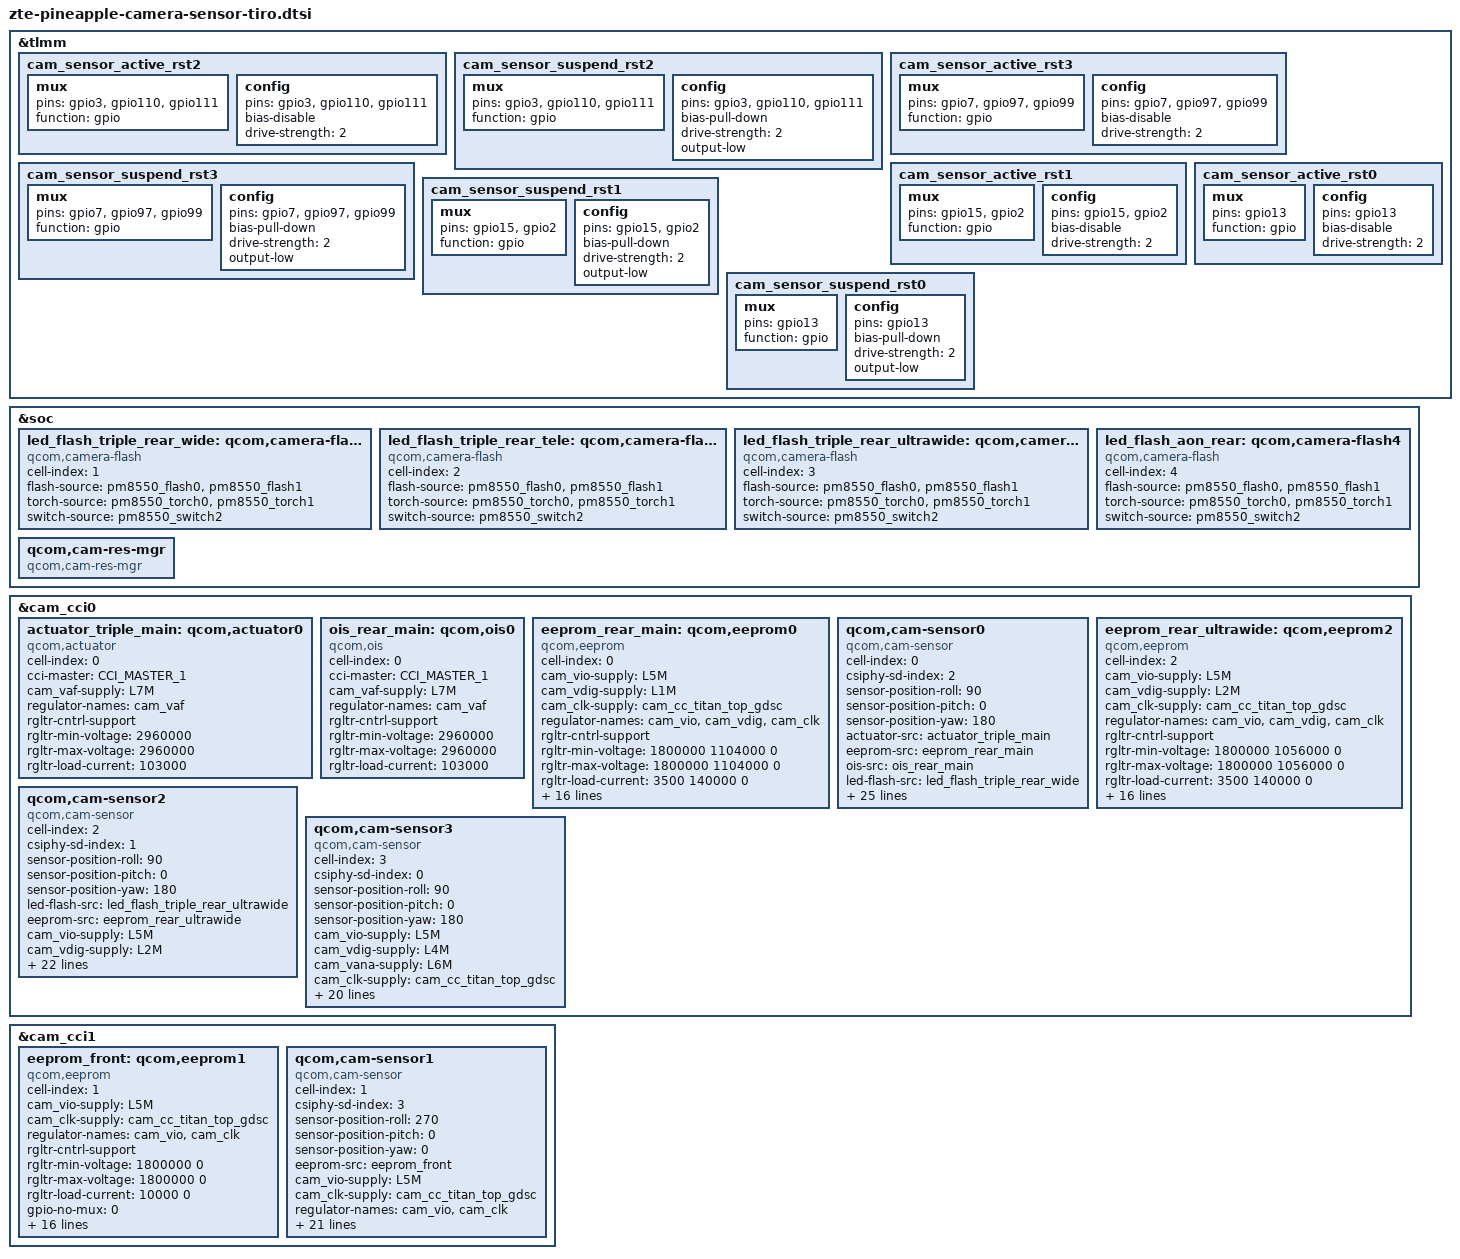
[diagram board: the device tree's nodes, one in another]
#include <dt-bindings/msm-camera.h>
&tlmm {
	cam_sensor_active_rst2: cam_sensor_active_rst2 {
		/* RESET 2 */
		mux {
			pins = "gpio3", "gpio110", "gpio111";
			function = "gpio";
		};

		config {
			pins = "gpio3", "gpio110", "gpio111";
			bias-disable; /* No PULL */
			drive-strength = <2>; /* 2 MA */
		};
	};

	cam_sensor_suspend_rst2: cam_sensor_suspend_rst2 {
		/* RESET 2 */
		mux {
			pins = "gpio3", "gpio110", "gpio111";
			function = "gpio";
		};

		config {
			pins = "gpio3", "gpio110", "gpio111";
			bias-pull-down; /* PULL DOWN */
			drive-strength = <2>; /* 2 MA */
			output-low;
		};
	};

	cam_sensor_active_rst3: cam_sensor_active_rst3 {
		/* RESET 3 */
		mux {
			pins = "gpio7", "gpio97", "gpio99";
			function = "gpio";
		};

		config {
			pins = "gpio7", "gpio97", "gpio99";
			bias-disable; /* No PULL */
			drive-strength = <2>; /* 2 MA */
		};
	};

	cam_sensor_suspend_rst3: cam_sensor_suspend_rst3 {
		/* RESET 3 */
		mux {
			pins = "gpio7", "gpio97", "gpio99";
			function = "gpio";
		};

		config {
			pins = "gpio7", "gpio97", "gpio99";
			bias-pull-down; /* PULL DOWN */
			drive-strength = <2>; /* 2 MA */
			output-low;
		};
	};

	cam_sensor_active_rst1: cam_sensor_active_rst1 {
		/* RESET 1 */
		mux {
			pins = "gpio15", "gpio2";
			function = "gpio";
		};

		config {
			pins = "gpio15", "gpio2";
			bias-disable; /* No PULL */
			drive-strength = <2>; /* 2 MA */
		};
	};

	cam_sensor_suspend_rst1: cam_sensor_suspend_rst1 {
		/* RESET 1 */
		mux {
			pins = "gpio15", "gpio2";
			function = "gpio";
		};

		config {
			pins = "gpio15", "gpio2";
			bias-pull-down; /* PULL DOWN */
			drive-strength = <2>; /* 2 MA */
			output-low;
		};
	};

	cam_sensor_active_rst0: cam_sensor_active_rst0 {
		/* RESET 0 */
		mux {
			pins = "gpio13";
			function = "gpio";
		};

		config {
			pins = "gpio13";
			bias-disable; /* No PULL */
			drive-strength = <2>; /* 2 MA */
		};
	};

	cam_sensor_suspend_rst0: cam_sensor_suspend_rst0 {
		/* RESET 0 */
		mux {
			pins = "gpio13";
			function = "gpio";
		};

		config {
			pins = "gpio13";
			bias-pull-down; /* PULL DOWN */
			drive-strength = <2>; /* 2 MA */
			output-low;
		};
	};
};

&soc {
	led_flash_triple_rear_wide: qcom,camera-flash1 {
		cell-index = <1>;
		compatible = "qcom,camera-flash";
		flash-source = <&pm8550_flash0 &pm8550_flash1>;
		torch-source = <&pm8550_torch0 &pm8550_torch1>;
		switch-source = <&pm8550_switch2>;
		status = "ok";
	};

	led_flash_triple_rear_tele: qcom,camera-flash2 {
		cell-index = <2>;
		compatible = "qcom,camera-flash";
		flash-source = <&pm8550_flash0 &pm8550_flash1>;
		torch-source = <&pm8550_torch0 &pm8550_torch1>;
		switch-source = <&pm8550_switch2>;
		status = "ok";
	};

	led_flash_triple_rear_ultrawide: qcom,camera-flash3 {
		cell-index = <3>;
		compatible = "qcom,camera-flash";
		flash-source = <&pm8550_flash0 &pm8550_flash1>;
		torch-source = <&pm8550_torch0 &pm8550_torch1>;
		switch-source = <&pm8550_switch2>;
		status = "ok";
	};

	led_flash_aon_rear: qcom,camera-flash4 {
		cell-index = <4>;
		compatible = "qcom,camera-flash";
		flash-source = <&pm8550_flash0 &pm8550_flash1>;
		torch-source = <&pm8550_torch0 &pm8550_torch1>;
		switch-source = <&pm8550_switch2>;
		status = "ok";
	};

	qcom,cam-res-mgr {
		compatible = "qcom,cam-res-mgr";
		status = "ok";
	};
};

&cam_cci0 {
//main
	actuator_triple_main: qcom,actuator0 {
		cell-index = <0>;
		compatible = "qcom,actuator";
		cci-master = <CCI_MASTER_1>;
		cam_vaf-supply = <&L7M>;
		regulator-names = "cam_vaf";
		rgltr-cntrl-support;
		rgltr-min-voltage = <2960000>;
		rgltr-max-voltage = <2960000>;
		rgltr-load-current = <103000>;
	};

	ois_rear_main: qcom,ois0 {
		cell-index = <0>;
		compatible = "qcom,ois";
		cci-master = <CCI_MASTER_1>;
		cam_vaf-supply = <&L7M>;
		regulator-names = "cam_vaf";
		rgltr-cntrl-support;
		rgltr-min-voltage = <2960000>;
		rgltr-max-voltage = <2960000>;
		rgltr-load-current = <103000>;
	};

	eeprom_rear_main: qcom,eeprom0 {
		cell-index = <0>;
		compatible = "qcom,eeprom";
		cam_vio-supply = <&L5M>;
		cam_vdig-supply = <&L1M>;
		cam_clk-supply = <&cam_cc_titan_top_gdsc>;
		regulator-names = "cam_vio", "cam_vdig", "cam_clk";
		rgltr-cntrl-support;
		rgltr-min-voltage = <1800000 1104000 0>;
		rgltr-max-voltage = <1800000 1104000 0>;
		rgltr-load-current = <3500 140000 0>;
		gpio-no-mux = <0>;
		pinctrl-names = "cam_default", "cam_suspend";
		pinctrl-0 = <&cam_sensor_mclk2_active
				 &cam_sensor_active_rst2>;
		pinctrl-1 = <&cam_sensor_mclk2_suspend
				 &cam_sensor_suspend_rst2>;
		gpios = <&tlmm 102 0>,
			<&tlmm 3 0>,
			<&tlmm 110 0>;
		gpio-reset = <1>;
		gpio-custom1 = <2>;
		gpio-req-tbl-num = <0 1 2>;
		gpio-req-tbl-flags = <1 0 0>;
		gpio-req-tbl-label = "CAMIF_MCLK2",
					"CAM_RESET2",
					"CAM_VANA2";
		cci-master = <CCI_MASTER_1>;
		clocks = <&camcc CAM_CC_MCLK2_CLK>;
		clock-names = "cam_clk";
		clock-cntl-level = "nominal";
		clock-rates = <19200000>;
		status = "ok";
	};

	qcom,cam-sensor0 {
		cell-index = <0>;
		compatible = "qcom,cam-sensor";
		csiphy-sd-index = <2>;
		sensor-position-roll = <90>;
		sensor-position-pitch = <0>;
		sensor-position-yaw = <180>;
		actuator-src = <&actuator_triple_main>;
		eeprom-src = <&eeprom_rear_main>;
		ois-src = <&ois_rear_main>;
		led-flash-src = <&led_flash_triple_rear_wide>;
		cam_vio-supply = <&L5M>;
		cam_vdig-supply = <&L1M>;
		cam_clk-supply = <&cam_cc_titan_top_gdsc>;
		regulator-names = "cam_vio", "cam_vdig", "cam_clk";
		rgltr-cntrl-support;
		rgltr-min-voltage = <1800000 1104000 0>;
		rgltr-max-voltage = <1800000 1104000 0>;
		rgltr-load-current = <3500 140000 0>;
		gpio-no-mux = <0>;
		pinctrl-names = "cam_default", "cam_suspend";
		pinctrl-0 = <&cam_sensor_mclk2_active
				 &cam_sensor_active_rst2>;
		pinctrl-1 = <&cam_sensor_mclk2_suspend
				 &cam_sensor_suspend_rst2>;
		gpios = <&tlmm 102 0>,
			<&tlmm 3 0>,
			<&tlmm 110 0>,
			<&tlmm 111 0>;
		gpio-reset = <1>;
		gpio-custom1 = <2>;
		gpio-standby = <3>;
		gpio-req-tbl-num = <0 1 2 3>;
		gpio-req-tbl-flags = <1 0 0 0>;
		gpio-req-tbl-label = "CAMIF_MCLK2",
					"CAM_RESET2",
					"CAM_VANA2",
					"CAM_STANDBY2";
		cci-master = <CCI_MASTER_1>;
		clocks = <&camcc CAM_CC_MCLK2_CLK>;
		clock-names = "cam_clk";
		clock-cntl-level = "nominal";
		clock-rates = <19200000>;
		status = "ok";
	};

//ultrawide
	eeprom_rear_ultrawide: qcom,eeprom2 {
		cell-index = <2>;
		compatible = "qcom,eeprom";
		cam_vio-supply = <&L5M>;
		cam_vdig-supply = <&L2M>;
		cam_clk-supply = <&cam_cc_titan_top_gdsc>;
		regulator-names = "cam_vio", "cam_vdig", "cam_clk";
		rgltr-cntrl-support;
		rgltr-min-voltage = <1800000 1056000 0>;
		rgltr-max-voltage = <1800000 1056000 0>;
		rgltr-load-current = <3500 140000 0>;
		gpio-no-mux = <0>;
		pinctrl-names = "cam_default", "cam_suspend";
		pinctrl-0 = <&cam_sensor_mclk1_active
				 &cam_sensor_active_rst1>;
		pinctrl-1 = <&cam_sensor_mclk1_suspend
				 &cam_sensor_suspend_rst1>;
		gpios = <&tlmm 101 0>,
			<&tlmm 15 0>,
			<&tlmm 2 0>;
		gpio-reset = <1>;
		gpio-custom1 = <2>;
		gpio-req-tbl-num = <0 1 2>;
		gpio-req-tbl-flags = <1 0 0>;
		gpio-req-tbl-label = "CAMIF_MCLK1",
					"CAM_RESET1",
					"CAM_VANA1";
		cci-master = <CCI_MASTER_0>;
		clocks = <&camcc CAM_CC_MCLK1_CLK>;
		clock-names = "cam_clk";
		clock-cntl-level = "nominal";
		clock-rates = <24000000>;
		status = "ok";
	};

	qcom,cam-sensor2 {
		cell-index = <2>;
		compatible = "qcom,cam-sensor";
		csiphy-sd-index = <1>;
		sensor-position-roll = <90>;
		sensor-position-pitch = <0>;
		sensor-position-yaw = <180>;
		led-flash-src = <&led_flash_triple_rear_ultrawide>;
		eeprom-src = <&eeprom_rear_ultrawide>;
		cam_vio-supply = <&L5M>;
		cam_vdig-supply = <&L2M>;
		cam_clk-supply = <&cam_cc_titan_top_gdsc>;
		regulator-names = "cam_vio", "cam_vdig", "cam_clk";
		rgltr-cntrl-support;
		rgltr-min-voltage = <1800000 1056000 0>;
		rgltr-max-voltage = <1800000 1056000 0>;
		rgltr-load-current = <3500 140000 0>;
		gpio-no-mux = <0>;
		pinctrl-names = "cam_default", "cam_suspend";
		pinctrl-0 = <&cam_sensor_mclk1_active
				 &cam_sensor_active_rst1>;
		pinctrl-1 = <&cam_sensor_mclk1_suspend
				 &cam_sensor_suspend_rst1>;
		gpios = <&tlmm 101 0>,
			<&tlmm 15 0>,
			<&tlmm 2 0>;
		gpio-reset = <1>;
		gpio-custom1 = <2>;
		gpio-req-tbl-num = <0 1 2>;
		gpio-req-tbl-flags = <1 0 0>;
		gpio-req-tbl-label = "CAMIF_MCLK1",
					"CAM_RESET1",
					"CAM_VANA1";
		cci-master = <CCI_MASTER_0>;
		clocks = <&camcc CAM_CC_MCLK1_CLK>;
		clock-names = "cam_clk";
		clock-cntl-level = "nominal";
		clock-rates = <24000000>;
		status = "ok";
	};

//aux
	qcom,cam-sensor3 {
		cell-index = <3>;
		compatible = "qcom,cam-sensor";
		csiphy-sd-index = <0>;
		sensor-position-roll = <90>;
		sensor-position-pitch = <0>;
		sensor-position-yaw = <180>;
		cam_vio-supply = <&L5M>;
		cam_vdig-supply = <&L4M>;
		cam_vana-supply = <&L6M>;
		cam_clk-supply = <&cam_cc_titan_top_gdsc>;
		regulator-names = "cam_vio", "cam_vdig", "cam_vana", "cam_clk";
		rgltr-cntrl-support;
		rgltr-min-voltage = <1800000 1800000 2800000 0>;
		rgltr-max-voltage = <1800000 1800000 2800000 0>;
		rgltr-load-current = <3500 140000 100000 0>;
		gpio-no-mux = <0>;
		pinctrl-names = "cam_default", "cam_suspend";
		pinctrl-0 = <&cam_sensor_mclk0_active
				 &cam_sensor_active_rst0>;
		pinctrl-1 = <&cam_sensor_mclk0_suspend
				 &cam_sensor_suspend_rst0>;
		gpios = <&tlmm 100 0>,
			<&tlmm 13 0>;
		gpio-reset = <1>;
		gpio-req-tbl-num = <0 1>;
		gpio-req-tbl-flags = <1 0>;
		gpio-req-tbl-label = "CAMIF_MCLK0",
					"CAM_RESET0";
		cci-master = <CCI_MASTER_0>;
		clocks = <&camcc CAM_CC_MCLK0_CLK>;
		clock-names = "cam_clk";
		clock-cntl-level = "nominal";
		clock-rates = <24000000>;
		status = "ok";
	};
};

&cam_cci1 {
//front
	eeprom_front: qcom,eeprom1 {
		cell-index = <1>;
		compatible = "qcom,eeprom";
		cam_vio-supply = <&L5M>;
		cam_clk-supply = <&cam_cc_titan_top_gdsc>;
		regulator-names = "cam_vio", "cam_clk";
		rgltr-cntrl-support;
		rgltr-min-voltage = <1800000 0>;
		rgltr-max-voltage = <1800000 0>;
		rgltr-load-current = <10000 0>;
		gpio-no-mux = <0>;
		pinctrl-names = "cam_default", "cam_suspend";
		pinctrl-0 = <&cam_sensor_mclk4_active
				 &cam_sensor_active_rst3>;
		pinctrl-1 = <&cam_sensor_mclk4_suspend
				 &cam_sensor_suspend_rst3>;
		gpios = <&tlmm 104 0>,
			<&tlmm 7 0>,
			<&tlmm 97 0>,
			<&tlmm 99 0>;
		gpio-reset = <1>;
		gpio-custom1 = <2>;
		gpio-standby = <3>;
		gpio-req-tbl-num = <0 1 2 3>;
		gpio-req-tbl-flags = <1 0 0 0>;
		gpio-req-tbl-label = "CAMIF_MCLK3",
					"CAM_RESET3",
					"CAM_VANA3",
					"CAM_STANDBY3";
		cci-master = <CCI_MASTER_0>;
		clocks = <&camcc CAM_CC_MCLK4_CLK>;
		clock-names = "cam_clk";
		clock-cntl-level = "nominal";
		clock-rates = <24000000>;
		status = "ok";
	};

	qcom,cam-sensor1 {
		cell-index = <1>;
		compatible = "qcom,cam-sensor";
		csiphy-sd-index = <3>;
		sensor-position-roll = <270>;
		sensor-position-pitch = <0>;
		sensor-position-yaw = <0>;
		eeprom-src = <&eeprom_front>;
		cam_vio-supply = <&L5M>;
		cam_clk-supply = <&cam_cc_titan_top_gdsc>;
		regulator-names = "cam_vio", "cam_clk";
		rgltr-cntrl-support;
		rgltr-min-voltage = <1800000 0>;
		rgltr-max-voltage = <1800000 0>;
		rgltr-load-current = <10000 0>;
		gpio-no-mux = <0>;
		pinctrl-names = "cam_default", "cam_suspend";
		pinctrl-0 = <&cam_sensor_mclk4_active
				 &cam_sensor_active_rst3>;
		pinctrl-1 = <&cam_sensor_mclk4_suspend
				 &cam_sensor_suspend_rst3>;
		gpios = <&tlmm 104 0>,
			<&tlmm 7 0>,
			<&tlmm 97 0>,
			<&tlmm 99 0>;
		gpio-reset = <1>;
		gpio-custom1 = <2>;
		gpio-standby = <3>;
		gpio-req-tbl-num = <0 1 2 3>;
		gpio-req-tbl-flags = <1 0 0 0>;
		gpio-req-tbl-label = "CAMIF_MCLK3",
					"CAM_RESET3",
					"CAM_VANA3",
					"CAM_STANDBY3";
		cci-master = <CCI_MASTER_0>;
		clocks = <&camcc CAM_CC_MCLK4_CLK>;
		clock-names = "cam_clk";
		clock-cntl-level = "nominal";
		clock-rates = <24000000>;
		status = "ok";
	};

};

